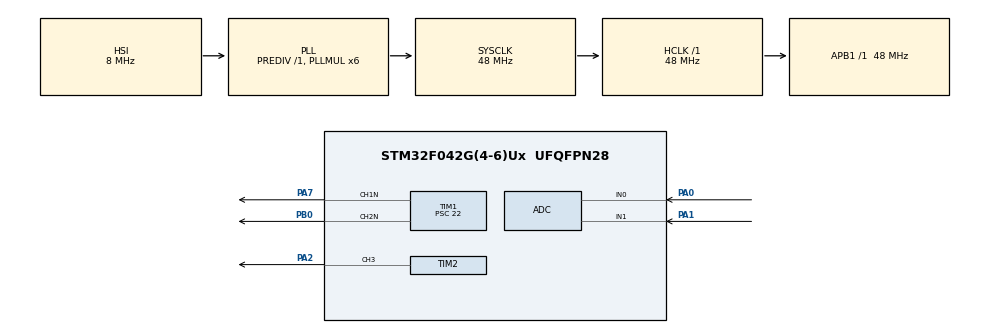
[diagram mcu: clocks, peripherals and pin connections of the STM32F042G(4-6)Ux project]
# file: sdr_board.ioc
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Mcu.Family=STM32F0
PA7.Mode=Output Compare1 CH1N
TIM1.OCMode_2=TIM_OCMODE_TOGGLE
TIM1.OCMode_1=TIM_OCMODE_TOGGLE
TIM2.Channel-Output\ Compare3\ CH3=TIM_CHANNEL_3
TIM1.OC2Preload=DISABLE
RCC.SYSCLKSource=RCC_SYSCLKSOURCE_PLLCLK
ProjectManager.StackSize=0x400
TIM1.ClockDivision=TIM_CLOCKDIVISION_DIV1
PB0.GPIO_Speed=GPIO_SPEED_FREQ_HIGH
TIM1.Prescaler=22
TIM1.Channel-Output\ Compare1\ CH1N=TIM_CHANNEL_1
TIM1.Pulse-Output\ Compare1\ CH1N=0
ProjectManager.TargetToolchain=Other Toolchains (GPDSC)
RCC.HCLKFreq_Value=48000000
TIM1.AutomaticOutput=TIM_AUTOMATICOUTPUT_DISABLE
TIM2.ClockDivision=TIM_CLOCKDIVISION_DIV4
TIM1.OC1Preload=DISABLE
PA1.Signal=ADC_IN1
RCC.AHBFreq_Value=48000000
PB0.Mode=Output Compare2 CH2N
board=custom
TIM1.LockLevel=TIM_LOCKLEVEL_OFF
TIM1.OCNPolarity_1=TIM_OCNPOLARITY_HIGH
RCC.PLLMUL=RCC_PLL_MUL6
PA7.GPIO_Speed=GPIO_SPEED_FREQ_HIGH
TIM1.OCNIdleState_2=TIM_OCNIDLESTATE_RESET
TIM1.OCNIdleState_1=TIM_OCNIDLESTATE_RESET
PA1.Mode=IN1
TIM1.OCNPolarity_2=TIM_OCNPOLARITY_HIGH
VP_TIM2_VS_ClockSourceINT.Mode=Internal
SH.S_TIM2_CH3.0=TIM2_CH3,Output Compare3 CH3
TIM2.Pulse-Output\ Compare3\ CH3=500
PA0.Mode=IN0
TIM2.Period=1000
Mcu.Name=STM32F042G(4-6)Ux
VP_TIM1_VS_ClockSourceINT.Mode=Internal
PA2.Signal=S_TIM2_CH3
PA0.Signal=ADC_IN0
RCC.SYSCLKFreq_VALUE=48000000
Mcu.Package=UFQFPN28
TIM2.Prescaler=10000
TIM2.OCMode_3=TIM_OCMODE_TOGGLE
ProjectManager.HeapSize=0x200
TIM1.BreakState=TIM_BREAK_DISABLE
RCC.APB1TimFreq_Value=48000000
TIM1.Period=1
TIM1.Channel-Output\ Compare2\ CH2N=TIM_CHANNEL_2
RCC.APB1Freq_Value=48000000
PB0.Signal=TIM1_CH2N
TIM1.Pulse-Output\ Compare2\ CH2N=1
PA7.Signal=TIM1_CH1N

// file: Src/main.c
/* USER CODE BEGIN Header */
/**
  ******************************************************************************
  * @file           : main.c
  * @brief          : Main program body
  ******************************************************************************
  * @attention
  *
  * <h2><center>&copy; Copyright (c) 2020 STMicroelectronics.
  * All rights reserved.</center></h2>
  *
  * This software component is licensed by ST under BSD 3-Clause license,
  * the "License"; You may not use this file except in compliance with the
  * License. You may obtain a copy of the License at:
  *                        opensource.org/licenses/BSD-3-Clause
  *
  ******************************************************************************
  */
/* USER CODE END Header */

#include "main.h"

ADC_HandleTypeDef hadc;

TIM_HandleTypeDef htim1;
TIM_HandleTypeDef htim2;

void SystemClock_Config(void);
static void MX_GPIO_Init(void);
static void MX_ADC_Init(void);
static void MX_TIM1_Init(void);
static void MX_TIM2_Init(void);

int main(void)
{

  /* MCU Configuration--------------------------------------------------------*/

  /* Reset of all peripherals, Initializes the Flash interface and the Systick. */
  HAL_Init();

  /* Configure the system clock */
  SystemClock_Config();

  /* Initialize all configured peripherals */
  MX_GPIO_Init();
  MX_ADC_Init();
  MX_TIM1_Init();
  MX_TIM2_Init();
  /* USER CODE BEGIN 2 */
  HAL_TIMEx_OCN_Start(&htim1, TIM_CHANNEL_1);
  HAL_TIMEx_OCN_Start(&htim1, TIM_CHANNEL_2);

  HAL_TIM_OC_Start(&htim2, TIM_CHANNEL_3);
  __HAL_RCC_HSI_CALIBRATIONVALUE_ADJUST(13);

  /* USER CODE END 2 */

  /* Infinite loop */
  while (1)
  {

  }
}

void SystemClock_Config(void)
{
  RCC_OscInitTypeDef RCC_OscInitStruct = {0};
  RCC_ClkInitTypeDef RCC_ClkInitStruct = {0};

  /** Initializes the CPU, AHB and APB busses clocks
  */
  RCC_OscInitStruct.OscillatorType = RCC_OSCILLATORTYPE_HSI|RCC_OSCILLATORTYPE_HSI14;
  RCC_OscInitStruct.HSIState = RCC_HSI_ON;
  RCC_OscInitStruct.HSI14State = RCC_HSI14_ON;
  RCC_OscInitStruct.HSICalibrationValue = RCC_HSICALIBRATION_DEFAULT;
  RCC_OscInitStruct.HSI14CalibrationValue = 16;
  RCC_OscInitStruct.PLL.PLLState = RCC_PLL_ON;
  RCC_OscInitStruct.PLL.PLLSource = RCC_PLLSOURCE_HSI;
  RCC_OscInitStruct.PLL.PLLMUL = RCC_PLL_MUL6;
  RCC_OscInitStruct.PLL.PREDIV = RCC_PREDIV_DIV1;
  if (HAL_RCC_OscConfig(&RCC_OscInitStruct) != HAL_OK)
  {
    Error_Handler();
  }
  /** Initializes the CPU, AHB and APB busses clocks
  */
  RCC_ClkInitStruct.ClockType = RCC_CLOCKTYPE_HCLK|RCC_CLOCKTYPE_SYSCLK
                              |RCC_CLOCKTYPE_PCLK1;
  RCC_ClkInitStruct.SYSCLKSource = RCC_SYSCLKSOURCE_PLLCLK;
  RCC_ClkInitStruct.AHBCLKDivider = RCC_SYSCLK_DIV1;
  RCC_ClkInitStruct.APB1CLKDivider = RCC_HCLK_DIV1;

  if (HAL_RCC_ClockConfig(&RCC_ClkInitStruct, FLASH_LATENCY_1) != HAL_OK)
  {
    Error_Handler();
  }
}

static void MX_ADC_Init(void)
{

  ADC_ChannelConfTypeDef sConfig = {0};

  /** Configure the global features of the ADC (Clock, Resolution, Data Alignment and number of conversion)
  */
  hadc.Instance = ADC1;
  hadc.Init.ClockPrescaler = ADC_CLOCK_ASYNC_DIV1;
  hadc.Init.Resolution = ADC_RESOLUTION_12B;
  hadc.Init.DataAlign = ADC_DATAALIGN_RIGHT;
  hadc.Init.ScanConvMode = ADC_SCAN_DIRECTION_FORWARD;
  hadc.Init.EOCSelection = ADC_EOC_SINGLE_CONV;
  hadc.Init.LowPowerAutoWait = DISABLE;
  hadc.Init.LowPowerAutoPowerOff = DISABLE;
  hadc.Init.ContinuousConvMode = DISABLE;
  hadc.Init.DiscontinuousConvMode = DISABLE;
  hadc.Init.ExternalTrigConv = ADC_SOFTWARE_START;
  hadc.Init.ExternalTrigConvEdge = ADC_EXTERNALTRIGCONVEDGE_NONE;
  hadc.Init.DMAContinuousRequests = DISABLE;
  hadc.Init.Overrun = ADC_OVR_DATA_PRESERVED;
  if (HAL_ADC_Init(&hadc) != HAL_OK)
  {
    Error_Handler();
  }
  /** Configure for the selected ADC regular channel to be converted.
  */
  sConfig.Channel = ADC_CHANNEL_0;
  sConfig.Rank = ADC_RANK_CHANNEL_NUMBER;
  sConfig.SamplingTime = ADC_SAMPLETIME_1CYCLE_5;
  if (HAL_ADC_ConfigChannel(&hadc, &sConfig) != HAL_OK)
  {
    Error_Handler();
  }
  /** Configure for the selected ADC regular channel to be converted.
  */
  sConfig.Channel = ADC_CHANNEL_1;
  if (HAL_ADC_ConfigChannel(&hadc, &sConfig) != HAL_OK)
  {
    Error_Handler();
  }

}

static void MX_TIM1_Init(void)
{

  TIM_ClockConfigTypeDef sClockSourceConfig = {0};
  TIM_MasterConfigTypeDef sMasterConfig = {0};
  TIM_OC_InitTypeDef sConfigOC = {0};
  TIM_BreakDeadTimeConfigTypeDef sBreakDeadTimeConfig = {0};

  htim1.Instance = TIM1;
  htim1.Init.Prescaler = 22;
  htim1.Init.CounterMode = TIM_COUNTERMODE_UP;
  htim1.Init.Period = 1;
  htim1.Init.ClockDivision = TIM_CLOCKDIVISION_DIV1;
  htim1.Init.RepetitionCounter = 0;
  htim1.Init.AutoReloadPreload = TIM_AUTORELOAD_PRELOAD_DISABLE;
  if (HAL_TIM_Base_Init(&htim1) != HAL_OK)
  {
    Error_Handler();
  }
  sClockSourceConfig.ClockSource = TIM_CLOCKSOURCE_INTERNAL;
  if (HAL_TIM_ConfigClockSource(&htim1, &sClockSourceConfig) != HAL_OK)
  {
    Error_Handler();
  }
  if (HAL_TIM_OC_Init(&htim1) != HAL_OK)
  {
    Error_Handler();
  }
  sMasterConfig.MasterOutputTrigger = TIM_TRGO_RESET;
  sMasterConfig.MasterSlaveMode = TIM_MASTERSLAVEMODE_DISABLE;
  if (HAL_TIMEx_MasterConfigSynchronization(&htim1, &sMasterConfig) != HAL_OK)
  {
    Error_Handler();
  }
  sConfigOC.OCMode = TIM_OCMODE_TOGGLE;
  sConfigOC.Pulse = 0;
  sConfigOC.OCPolarity = TIM_OCPOLARITY_HIGH;
  sConfigOC.OCNPolarity = TIM_OCNPOLARITY_HIGH;
  sConfigOC.OCFastMode = TIM_OCFAST_DISABLE;
  sConfigOC.OCIdleState = TIM_OCIDLESTATE_RESET;
  sConfigOC.OCNIdleState = TIM_OCNIDLESTATE_RESET;
  if (HAL_TIM_OC_ConfigChannel(&htim1, &sConfigOC, TIM_CHANNEL_1) != HAL_OK)
  {
    Error_Handler();
  }
  sConfigOC.Pulse = 1;
  if (HAL_TIM_OC_ConfigChannel(&htim1, &sConfigOC, TIM_CHANNEL_2) != HAL_OK)
  {
    Error_Handler();
  }
  sBreakDeadTimeConfig.OffStateRunMode = TIM_OSSR_DISABLE;
  sBreakDeadTimeConfig.OffStateIDLEMode = TIM_OSSI_DISABLE;
  sBreakDeadTimeConfig.LockLevel = TIM_LOCKLEVEL_OFF;
  sBreakDeadTimeConfig.DeadTime = 0;
  sBreakDeadTimeConfig.BreakState = TIM_BREAK_DISABLE;
  sBreakDeadTimeConfig.BreakPolarity = TIM_BREAKPOLARITY_HIGH;
  sBreakDeadTimeConfig.AutomaticOutput = TIM_AUTOMATICOUTPUT_DISABLE;
  if (HAL_TIMEx_ConfigBreakDeadTime(&htim1, &sBreakDeadTimeConfig) != HAL_OK)
  {
    Error_Handler();
  }
  HAL_TIM_MspPostInit(&htim1);

}

static void MX_TIM2_Init(void)
{

  TIM_ClockConfigTypeDef sClockSourceConfig = {0};
  TIM_MasterConfigTypeDef sMasterConfig = {0};
  TIM_OC_InitTypeDef sConfigOC = {0};

  htim2.Instance = TIM2;
  htim2.Init.Prescaler = 10000;
  htim2.Init.CounterMode = TIM_COUNTERMODE_UP;
  htim2.Init.Period = 1000;
  htim2.Init.ClockDivision = TIM_CLOCKDIVISION_DIV4;
  htim2.Init.AutoReloadPreload = TIM_AUTORELOAD_PRELOAD_DISABLE;
  if (HAL_TIM_Base_Init(&htim2) != HAL_OK)
  {
    Error_Handler();
  }
  sClockSourceConfig.ClockSource = TIM_CLOCKSOURCE_INTERNAL;
  if (HAL_TIM_ConfigClockSource(&htim2, &sClockSourceConfig) != HAL_OK)
  {
    Error_Handler();
  }
  if (HAL_TIM_OC_Init(&htim2) != HAL_OK)
  {
    Error_Handler();
  }
  sMasterConfig.MasterOutputTrigger = TIM_TRGO_RESET;
  sMasterConfig.MasterSlaveMode = TIM_MASTERSLAVEMODE_DISABLE;
  if (HAL_TIMEx_MasterConfigSynchronization(&htim2, &sMasterConfig) != HAL_OK)
  {
    Error_Handler();
  }
  sConfigOC.OCMode = TIM_OCMODE_TOGGLE;
  sConfigOC.Pulse = 500;
  sConfigOC.OCPolarity = TIM_OCPOLARITY_HIGH;
  sConfigOC.OCFastMode = TIM_OCFAST_DISABLE;
  if (HAL_TIM_OC_ConfigChannel(&htim2, &sConfigOC, TIM_CHANNEL_3) != HAL_OK)
  {
    Error_Handler();
  }
  HAL_TIM_MspPostInit(&htim2);

}

static void MX_GPIO_Init(void)
{

  /* GPIO Ports Clock Enable */
  __HAL_RCC_GPIOA_CLK_ENABLE();
  __HAL_RCC_GPIOB_CLK_ENABLE();

}

void Error_Handler(void)
{
}

/************************ (C) COPYRIGHT STMicroelectronics *****END OF FILE****/
